# STM32L412C8T6 register map
File version: 1.0
Registers are 32-bit, access not given, reset 0x0 unless marked. A register's access mark holds for its fields unless they carry their own. Offsets are from the block's base; [hi:lo] are bit positions; {n}, {i} and the like mark numbered series; 'fields as' and 'values as' point back to an identical list.

## TIM6
Base 0x40001000
Same registers: TIM7 0x40001400
0x00 CR1
  [11] UIFREMAP, [7] ARPE, [31:4] s, [3] OPM, [2] URS, [1] UDIS, [0] CEN
0x04 CR2
  [6:4] MMS, [31:0] s
0x0C DIER
  [8] UDE, [31:1] s, [0] UIE
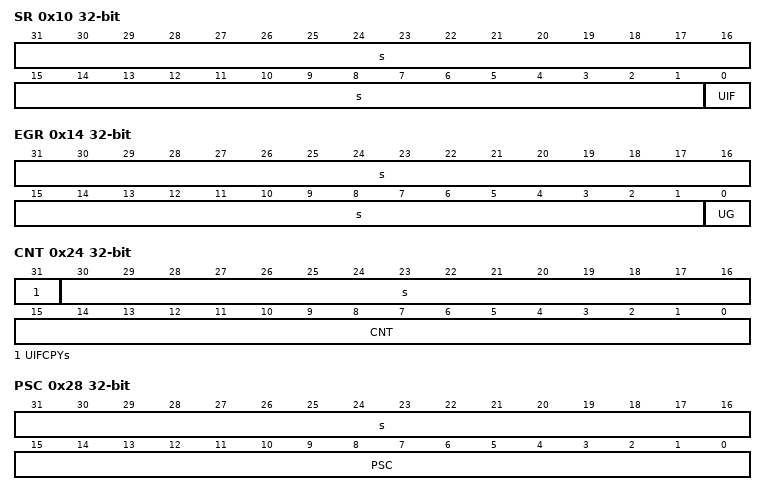
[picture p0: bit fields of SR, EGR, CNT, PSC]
0x10 SR
  [31:1] s, [0] UIF
0x14 EGR
  [31:1] s, [0] UG
0x24 CNT
  [31] UIFCPYs, [30:16] s, [15:0] CNT
0x28 PSC
  [31:16] s, [15:0] PSC
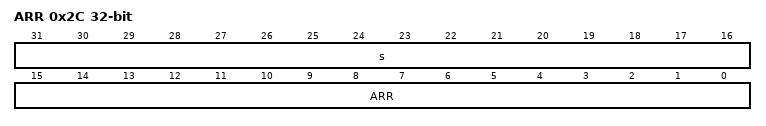
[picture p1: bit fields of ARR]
0x2C ARR
  [31:16] s, [15:0] ARR

## LCD
Base 0x40002400
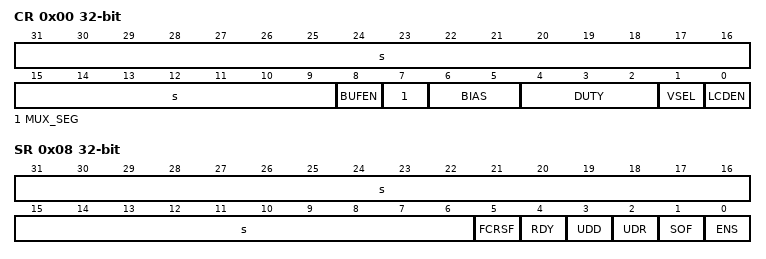
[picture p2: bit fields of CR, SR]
0x00 CR
  [31:9] s, [8] BUFEN, [7] MUX_SEG, [6:5] BIAS, [4:2] DUTY, [1] VSEL, [0] LCDEN
0x04 FCR
  [25:22] PS, [21:18] DIV, [17:16] BLINK, [15:13] BLINKF, [12:10] CC, [9:7] DEAD, [6:4] PON, [3] UDDIE, [31:2] s, [1] SOFIE, [0] HD
0x08 SR
  [31:6] s, [5] FCRSF, [4] RDY, [3] UDD, [2] UDR, [1] SOF, [0] ENS
0x0C CLR
  [3] UDDC, [1] SOFC, [31:0] s
{0x18+8i} RAM_COM{i} (i=0..7)

## RTC
Base 0x40002800
0x00 TR
  [22] PM, [21:20] HT, [19:16] HU, [14:12] MNT, [11:8] MNU, [31:7] s, [6:4] ST, [3:0] SU
0x04 DR
  [23:20] YT, [19:16] YU, [15:13] WDU, [12] MT, [11:8] MU, [31:6] s, [5:4] DT, [3:0] DU
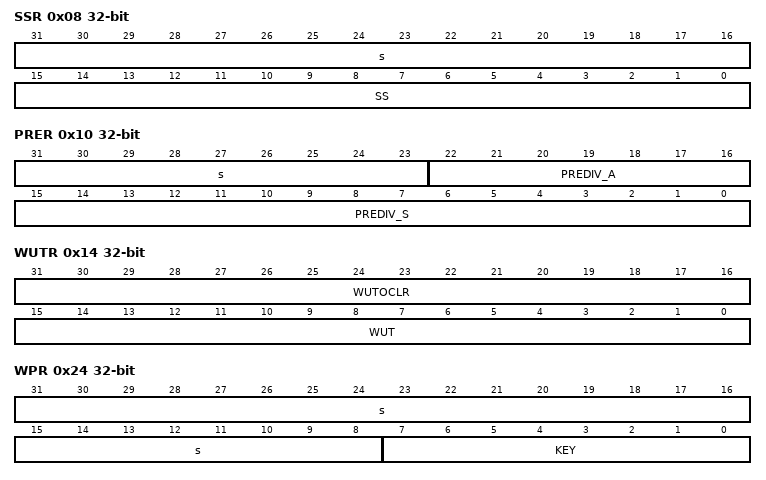
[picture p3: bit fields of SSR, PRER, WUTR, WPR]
0x08 SSR
  [31:16] s, [15:0] SS
0x0C ICSR
  [16] RECALPF, [7] INIT, [6] INITF, [5] RSF, [4] INITS, [3] SHPF, [2] WUTWF, [31:0] s
0x10 PRER
  [31:23] s, [22:16] PREDIV_A, [15:0] PREDIV_S
0x14 WUTR
  [31:16] WUTOCLR, [15:0] WUT
0x18 CR
  [31] OUT2EN, [30] TAMPALRM_TYPE, [29] TAMPALRM_PU, [26] TAMPOE, [25] TAMPTS, [24] ITSE, [23] COE, [22:21] OSEL, [20] POL, [19] COSEL, [18] BKP, [17] SUB1H, [16] ADD1H, [15] TSIE, [14] WUTIE, [13] ALRBIE, [12] ALRAIE, [11] TSE, [10] WUTE, [9] ALRBE, [8] ALRAE, [28:7] s, [6] FMT, [5] BYPSHAD, [4] REFCKON, [3] TSEDGE, [2:0] WUCKSEL
0x24 WPR
  [31:8] s, [7:0] KEY
0x28 CALR
  [15] CALP, [14] CALW8, [13] CALW16, [12] LPCAL, [31:9] s, [8:0] CALM
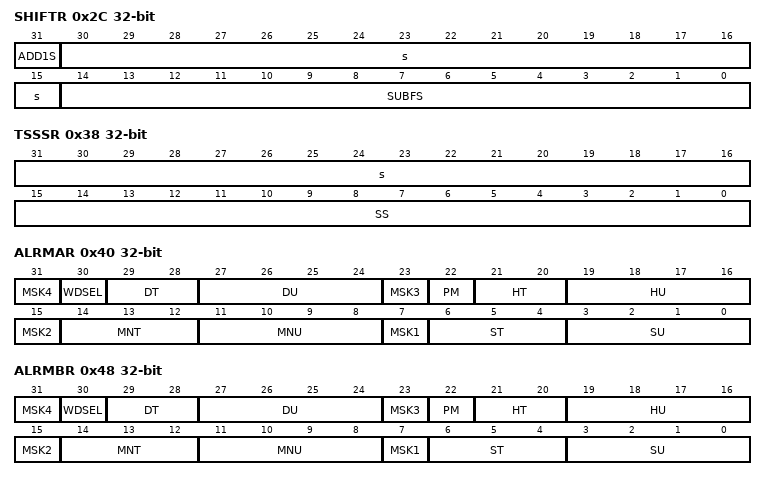
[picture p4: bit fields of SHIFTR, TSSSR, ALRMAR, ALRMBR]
0x2C SHIFTR
  [31] ADD1S, [30:15] s, [14:0] SUBFS
0x30 TSTR
  fields as TR
0x34 TSDR
  [15:13] WDU, [12] MT, [11:8] MU, [31:6] s, [5:4] DT, [3:0] DU
0x38 TSSSR
  [31:16] s, [15:0] SS
0x40 ALRMAR
  [8n-1] MSK{n} (n=1..4), [30] WDSEL, [29:28] DT, [27:24] DU, [22] PM, [21:20] HT, [19:16] HU, [14:12] MNT, [11:8] MNU, [6:4] ST, [3:0] SU
0x44 ALRMASSR
  [27:24] MASKSS, [31:15] s, [14:0] SS
0x48 ALRMBR
  fields as ALRMAR
0x4C ALRMBSSR
  [27:24] MASKSS, [31:15] s, [14:0] SS
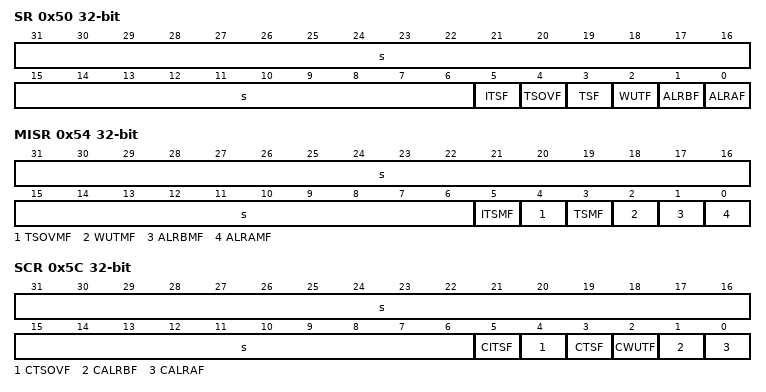
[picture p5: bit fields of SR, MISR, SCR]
0x50 SR
  [31:6] s, [5] ITSF, [4] TSOVF, [3] TSF, [2] WUTF, [1] ALRBF, [0] ALRAF
0x54 MISR
  [31:6] s, [5] ITSMF, [4] TSOVMF, [3] TSMF, [2] WUTMF, [1] ALRBMF, [0] ALRAMF
0x5C SCR
  [31:6] s, [5] CITSF, [4] CTSOVF, [3] CTSF, [2] CWUTF, [1] CALRBF, [0] CALRAF

## WWDG
Base 0x40002C00
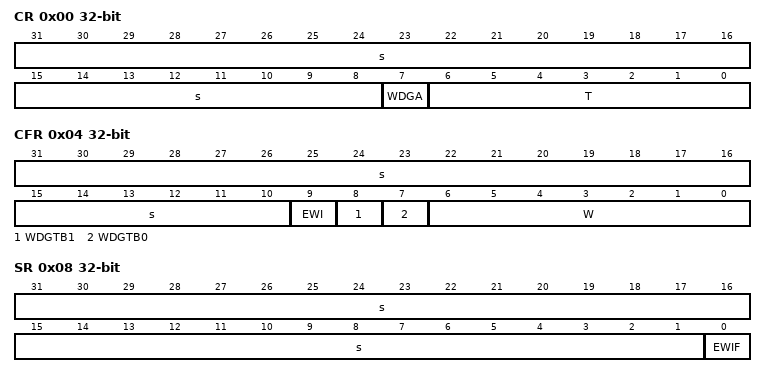
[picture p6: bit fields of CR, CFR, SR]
0x00 CR
  [31:8] s, [7] WDGA, [6:0] T
0x04 CFR
  [31:10] s, [9] EWI, [8] WDGTB1, [7] WDGTB0, [6:0] W
0x08 SR
  [31:1] s, [0] EWIF

## IWDG
Base 0x40003000
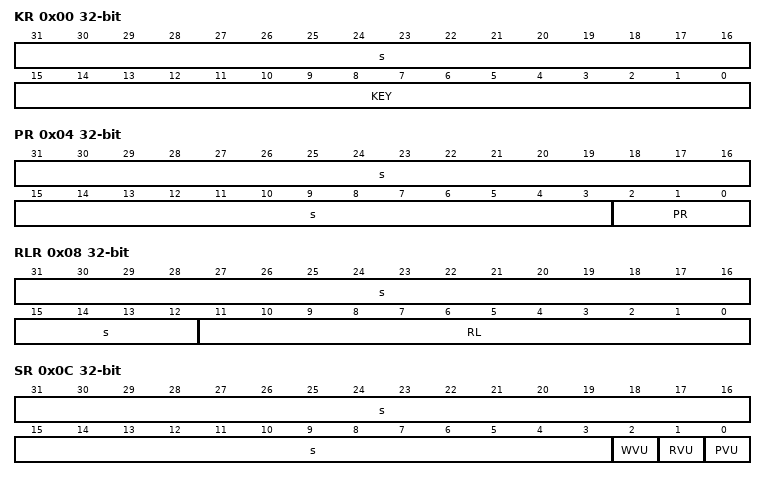
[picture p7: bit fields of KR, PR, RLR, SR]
0x00 KR
  [31:16] s, [15:0] KEY
0x04 PR
  [31:3] s, [2:0] PR
0x08 RLR
  [31:12] s, [11:0] RL
0x0C SR
  [31:3] s, [2] WVU, [1] RVU, [0] PVU
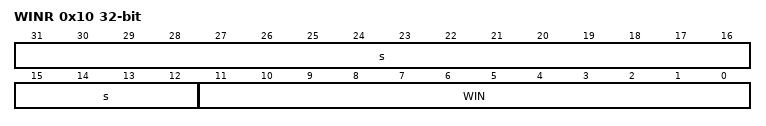
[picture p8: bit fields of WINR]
0x10 WINR
  [31:12] s, [11:0] WIN

## SPI2
Base 0x40003800
Same registers: SPI3 0x40003C00, SPI1 0x40013000
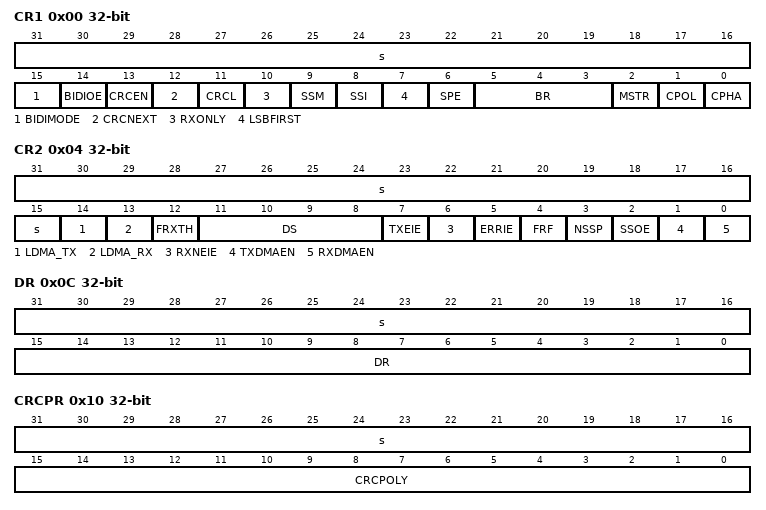
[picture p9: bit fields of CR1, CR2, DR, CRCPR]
0x00 CR1
  [31:16] s, [15] BIDIMODE, [14] BIDIOE, [13] CRCEN, [12] CRCNEXT, [11] CRCL, [10] RXONLY, [9] SSM, [8] SSI, [7] LSBFIRST, [6] SPE, [5:3] BR, [2] MSTR, [1] CPOL, [0] CPHA
0x04 CR2
  [31:15] s, [14] LDMA_TX, [13] LDMA_RX, [12] FRXTH, [11:8] DS, [7] TXEIE, [6] RXNEIE, [5] ERRIE, [4] FRF, [3] NSSP, [2] SSOE, [1] TXDMAEN, [0] RXDMAEN
0x08 SR
  [12:11] FTLVL, [10:9] FRLVL, [8] FRE, [7] BSY, [6] OVR, [5] MODF, [4] CRCERR, [31:2] s, [1] TXE, [0] RXNE
0x0C DR
  [31:16] s, [15:0] DR
0x10 CRCPR
  [31:16] s, [15:0] CRCPOLY
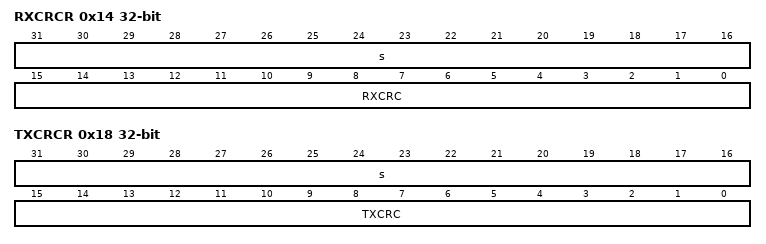
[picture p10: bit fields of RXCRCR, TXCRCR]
0x14 RXCRCR
  [31:16] s, [15:0] RXCRC
0x18 TXCRCR
  [31:16] s, [15:0] TXCRC

## USART2
Base 0x40004400
Same registers: USART3 0x40004800, USART4 0x40004C00, USART1 0x40013800
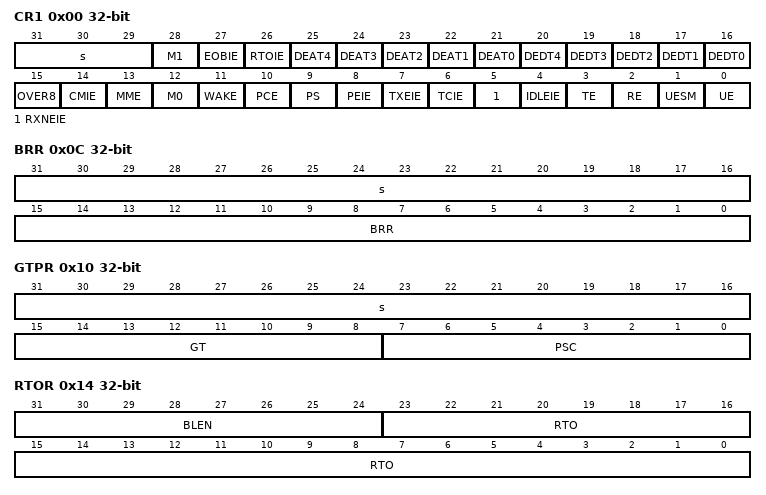
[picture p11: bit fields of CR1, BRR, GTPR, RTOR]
0x00 CR1
  [31:29] s, [28] M1, [27] EOBIE, [26] RTOIE, [n+21] DEAT{n} (n=0..4), [n+16] DEDT{n} (n=0..4), [15] OVER8, [14] CMIE, [13] MME, [12] M0, [11] WAKE, [10] PCE, [9] PS, [8] PEIE, [7] TXEIE, [6] TCIE, [5] RXNEIE, [4] IDLEIE, [3] TE, [2] RE, [1] UESM, [0] UE
0x04 CR2
  [31:24] ADD, [23] RTOEN, [22] ABRMOD1, [21] ABRMOD0, [20] ABREN, [19] MSBFIRST, [18] DATAINV, [17] TXINV, [16] RXINV, [15] SWAP, [14] LINEN, [13:12] STOP, [11] CLKEN, [10] CPOL, [9] CPHA, [8] LBCL, [6] LBDIE, [5] LBDL, [4] ADDM7, [7:0] s
0x08 CR3
  [24] TCBGTIE, [23] UCESM, [22] WUFIE, [21:20] WUS, [19:17] SCARCNT, [31:16] s, [15] DEP, [14] DEM, [13] DDRE, [12] OVRDIS, [11] ONEBIT, [10] CTSIE, [9] CTSE, [8] RTSE, [7] DMAT, [6] DMAR, [5] SCEN, [4] NACK, [3] HDSEL, [2] IRLP, [1] IREN, [0] EIE
0x0C BRR
  [31:16] s, [15:0] BRR
0x10 GTPR
  [31:16] s, [15:8] GT, [7:0] PSC
0x14 RTOR
  [31:24] BLEN, [23:0] RTO
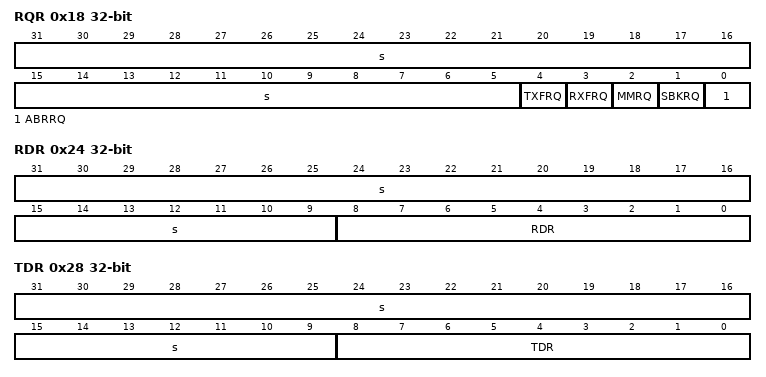
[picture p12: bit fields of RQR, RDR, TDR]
0x18 RQR
  [31:5] s, [4] TXFRQ, [3] RXFRQ, [2] MMRQ, [1] SBKRQ, [0] ABRRQ
0x1C ISR
  [25] TCBGT, [22] REACK, [21] TEACK, [20] WUF, [19] RWU, [18] SBKF, [17] CMF, [16] BUSY, [15] ABRF, [14] ABRE, [31:13] s, [12] EOBF, [11] RTOF, [10] CTS, [9] CTSIF, [8] LBDF, [7] TXE, [6] TC, [5] RXNE, [4] IDLE, [3] ORE, [2] NF, [1] FE, [0] PE
0x20 ICR
  [20] WUCF, [17] CMCF, [12] EOBCF, [11] RTOCF, [9] CTSCF, [8] LBDCF, [7] TCBGTCF, [6] TCCF, [31:5] s, [4] IDLECF, [3] ORECF, [2] NCF, [1] FECF, [0] PECF
0x24 RDR
  [31:9] s, [8:0] RDR
0x28 TDR
  [31:9] s, [8:0] TDR
